# TMS320F280049 register map
Vendor: Texas Instruments; Series: C2000 F28004x; File version: 0.2.0-generated
Registers are 16-bit, read-write, reset 0x0 unless marked. A register's access mark holds for its fields unless they carry their own. Offsets are from the block's base; [hi:lo] are bit positions; {n}, {i} and the like mark numbered series.

## EPWMXBARREGS — EPWM XBAR Registers
Base 0x0000F400
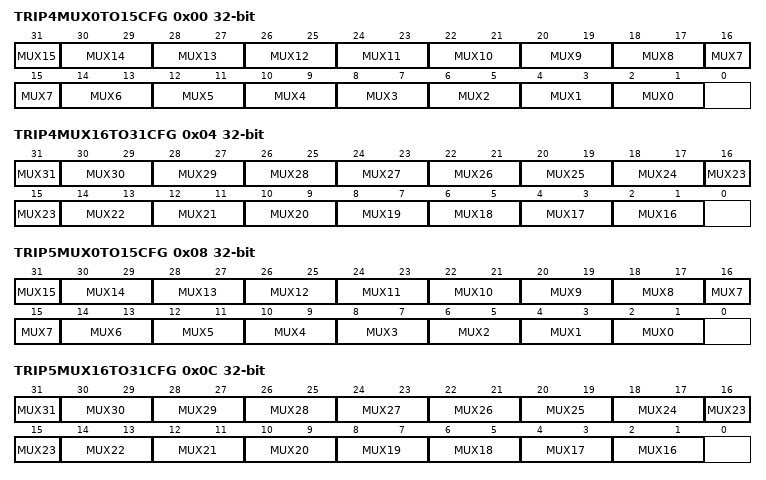
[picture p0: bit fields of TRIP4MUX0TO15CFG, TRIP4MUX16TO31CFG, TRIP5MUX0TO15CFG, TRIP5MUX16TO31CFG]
0x00 TRIP4MUX0TO15CFG 32-bit — ePWM XBAR Mux Configuration for TRIP4
  [31] MUX15 — Mux15 Configuration for TRIP4 of EPWM-XBAR
  [2n+2:2n+1] MUX{n} (n=0..14) — Mux{n} Configuration for TRIP4 of EPWM-XBAR
0x04 TRIP4MUX16TO31CFG 32-bit — ePWM XBAR Mux Configuration for TRIP4
  [31] MUX31 — Mux31 Configuration for TRIP4 of EPWM-XBAR
  [2n-30:2n-31] MUX{n} (n=16..30) — Mux{n} Configuration for TRIP4 of EPWM-XBAR
0x08 TRIP5MUX0TO15CFG 32-bit — ePWM XBAR Mux Configuration for TRIP5
  [31] MUX15 — Mux15 Configuration for TRIP5 of EPWM-XBAR
  [2n+2:2n+1] MUX{n} (n=0..14) — Mux{n} Configuration for TRIP5 of EPWM-XBAR
0x0C TRIP5MUX16TO31CFG 32-bit — ePWM XBAR Mux Configuration for TRIP5
  [31] MUX31 — Mux31 Configuration for TRIP5 of EPWM-XBAR
  [2n-30:2n-31] MUX{n} (n=16..30) — Mux{n} Configuration for TRIP5 of EPWM-XBAR
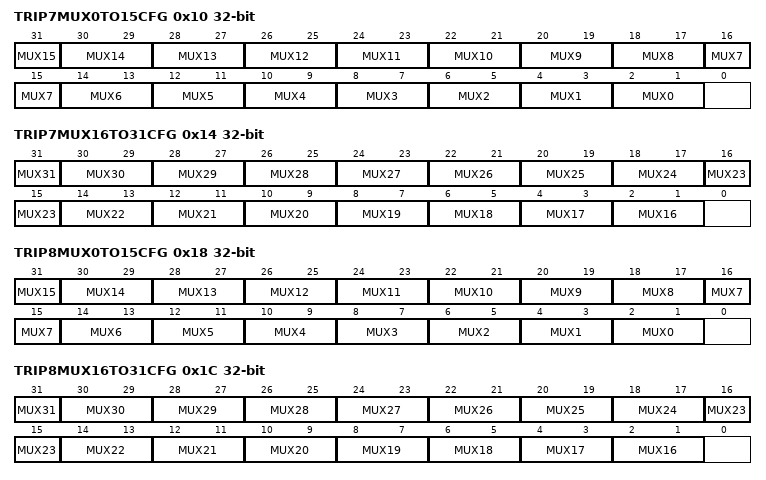
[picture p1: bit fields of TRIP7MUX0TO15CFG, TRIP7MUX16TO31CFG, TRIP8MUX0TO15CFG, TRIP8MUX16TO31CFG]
0x10 TRIP7MUX0TO15CFG 32-bit — ePWM XBAR Mux Configuration for TRIP7
  [31] MUX15 — Mux15 Configuration for TRIP7 of EPWM-XBAR
  [2n+2:2n+1] MUX{n} (n=0..14) — Mux{n} Configuration for TRIP7 of EPWM-XBAR
0x14 TRIP7MUX16TO31CFG 32-bit — ePWM XBAR Mux Configuration for TRIP7
  [31] MUX31 — Mux31 Configuration for TRIP7 of EPWM-XBAR
  [2n-30:2n-31] MUX{n} (n=16..30) — Mux{n} Configuration for TRIP7 of EPWM-XBAR
0x18 TRIP8MUX0TO15CFG 32-bit — ePWM XBAR Mux Configuration for TRIP8
  [31] MUX15 — Mux15 Configuration for TRIP8 of EPWM-XBAR
  [2n+2:2n+1] MUX{n} (n=0..14) — Mux{n} Configuration for TRIP8 of EPWM-XBAR
0x1C TRIP8MUX16TO31CFG 32-bit — ePWM XBAR Mux Configuration for TRIP8
  [31] MUX31 — Mux31 Configuration for TRIP8 of EPWM-XBAR
  [2n-30:2n-31] MUX{n} (n=16..30) — Mux{n} Configuration for TRIP8 of EPWM-XBAR
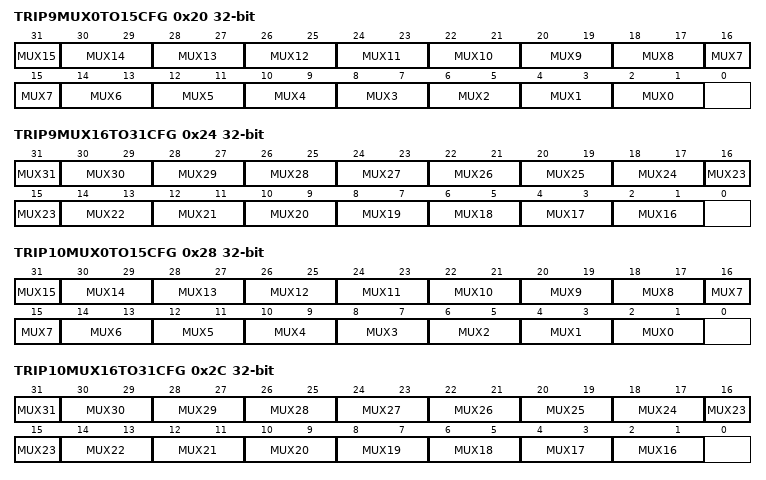
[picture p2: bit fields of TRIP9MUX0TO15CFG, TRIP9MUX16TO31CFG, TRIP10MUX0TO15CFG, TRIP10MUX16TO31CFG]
0x20 TRIP9MUX0TO15CFG 32-bit — ePWM XBAR Mux Configuration for TRIP9
  [31] MUX15 — Mux15 Configuration for TRIP9 of EPWM-XBAR
  [2n+2:2n+1] MUX{n} (n=0..14) — Mux{n} Configuration for TRIP9 of EPWM-XBAR
0x24 TRIP9MUX16TO31CFG 32-bit — ePWM XBAR Mux Configuration for TRIP9
  [31] MUX31 — Mux31 Configuration for TRIP9 of EPWM-XBAR
  [2n-30:2n-31] MUX{n} (n=16..30) — Mux{n} Configuration for TRIP9 of EPWM-XBAR
0x28 TRIP10MUX0TO15CFG 32-bit — ePWM XBAR Mux Configuration for TRIP10
  [31] MUX15 — Mux15 Configuration for TRIP10 of EPWM-XBAR
  [2n+2:2n+1] MUX{n} (n=0..14) — Mux{n} Configuration for TRIP10 of EPWM-XBAR
0x2C TRIP10MUX16TO31CFG 32-bit — ePWM XBAR Mux Configuration for TRIP10
  [31] MUX31 — Mux31 Configuration for TRIP10 of EPWM-XBAR
  [2n-30:2n-31] MUX{n} (n=16..30) — Mux{n} Configuration for TRIP10 of EPWM-XBAR
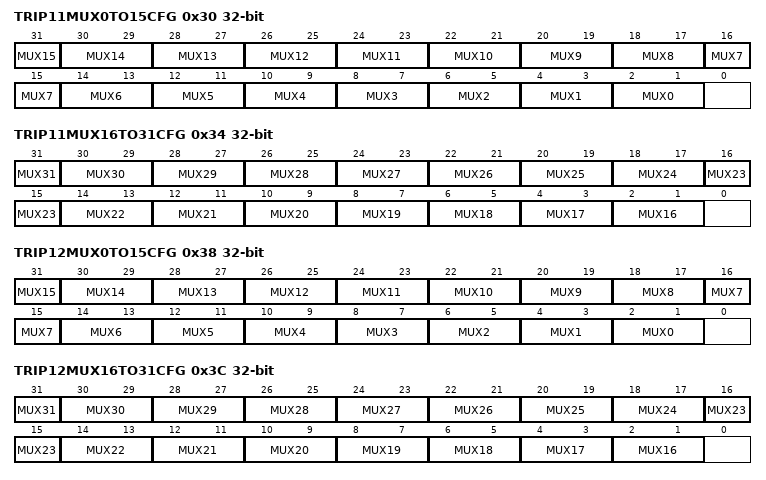
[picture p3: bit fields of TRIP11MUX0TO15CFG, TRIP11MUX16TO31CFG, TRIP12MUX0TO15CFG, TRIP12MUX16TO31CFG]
0x30 TRIP11MUX0TO15CFG 32-bit — ePWM XBAR Mux Configuration for TRIP11
  [31] MUX15 — Mux15 Configuration for TRIP11 of EPWM-XBAR
  [2n+2:2n+1] MUX{n} (n=0..14) — Mux{n} Configuration for TRIP11 of EPWM-XBAR
0x34 TRIP11MUX16TO31CFG 32-bit — ePWM XBAR Mux Configuration for TRIP11
  [31] MUX31 — Mux31 Configuration for TRIP11 of EPWM-XBAR
  [2n-30:2n-31] MUX{n} (n=16..30) — Mux{n} Configuration for TRIP11 of EPWM-XBAR
0x38 TRIP12MUX0TO15CFG 32-bit — ePWM XBAR Mux Configuration for TRIP12
  [31] MUX15 — Mux15 Configuration for TRIP12 of EPWM-XBAR
  [2n+2:2n+1] MUX{n} (n=0..14) — Mux{n} Configuration for TRIP12 of EPWM-XBAR
0x3C TRIP12MUX16TO31CFG 32-bit — ePWM XBAR Mux Configuration for TRIP12
  [31] MUX31 — Mux31 Configuration for TRIP12 of EPWM-XBAR
  [2n-30:2n-31] MUX{n} (n=16..30) — Mux{n} Configuration for TRIP12 of EPWM-XBAR
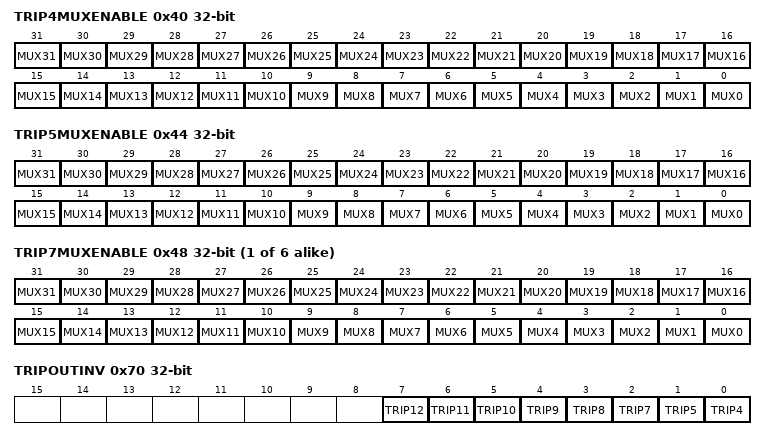
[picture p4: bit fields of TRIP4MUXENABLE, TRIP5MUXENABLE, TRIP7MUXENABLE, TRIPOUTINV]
0x40 TRIP4MUXENABLE 32-bit — ePWM XBAR Mux Enable for TRIP4
  [n] MUX{n} (n=1..31) — Mux{n} to drive TRIP4 of EPWM-XBAR
  [0] MUX0 — mux0 to drive TRIP4 of EPWM-XBAR
0x44 TRIP5MUXENABLE 32-bit — ePWM XBAR Mux Enable for TRIP5
  [n] MUX{n} (n=1..31) — Mux{n} to drive TRIP5 of EPWM-XBAR
  [0] MUX0 — mux0 to drive TRIP5 of EPWM-XBAR
{0x2C+4i} TRIP{i}MUXENABLE 32-bit (i=7..12) — ePWM XBAR Mux Enable for TRIP{i}
  [n] MUX{n} (n=1..31) — Mux{n} to drive TRIP{i} of EPWM-XBAR
  [0] MUX0 — mux0 to drive TRIP{i} of EPWM-XBAR
0x70 TRIPOUTINV 32-bit — ePWM XBAR Output Inversion Register
  [n-5] TRIP{n} (n=7..12) — Selects polarity for TRIP{n} of EPWM-XBAR
  [1] TRIP5 — Selects polarity for TRIP5 of EPWM-XBAR
  [0] TRIP4 — Selects polarity for TRIP4 of EPWM-XBAR
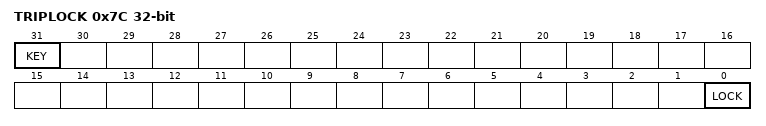
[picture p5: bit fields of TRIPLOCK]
0x7C TRIPLOCK 32-bit — ePWM XBAR Configuration Lock register
  [31] KEY — Write protection KEY
  [0] LOCK — Locks the configuration for EPWM-XBAR
